# ioat91sam7s64 register map
Registers are 32-bit, access not given, no defined reset value unless marked. A register's access mark holds for its fields unless they carry their own. Addresses are absolute; registers are grouped by the start of their names; [hi:lo] are bit positions; {n}, {i} and the like mark numbered series; 'fields as' and 'values as' point back to an identical list.

## RSTC
0xFFFFFD00 RSTC_RCR 40-bit
  [32:24] KEY, [3] EXTRST, [2] PERRST, [1] ICERST, [0] PROCRST
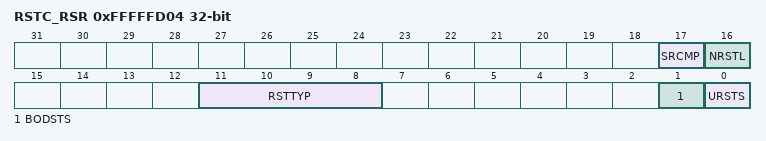
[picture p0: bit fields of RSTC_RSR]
0xFFFFFD04 RSTC_RSR
  [17] SRCMP, [16] NRSTL, [11:8] RSTTYP, [1] BODSTS, [0] URSTS
0xFFFFFD08 RSTC_RMR 40-bit
  [32:24] KEY, [16] BODIEN, [12:8] ERSTL, [4] URSTIEN, [0] URSTEN

## RTTC
0xFFFFFD20 RTTC_RTMR
  [18] RTTRST, [17] RTTINCIEN, [16] ALMIEN, [16:0] RTPRES
0xFFFFFD24 RTTC_RTAR 40-bit
  [32:0] ALMV
0xFFFFFD28 RTTC_RTVR 40-bit
  [32:0] CRTV
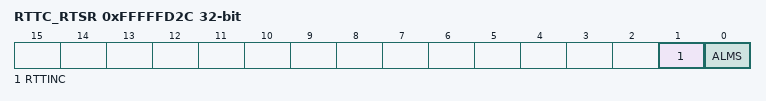
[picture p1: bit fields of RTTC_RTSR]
0xFFFFFD2C RTTC_RTSR
  [1] RTTINC, [0] ALMS

## PITC
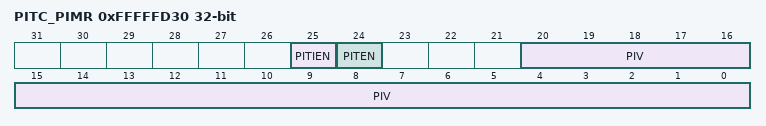
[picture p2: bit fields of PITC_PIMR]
0xFFFFFD30 PITC_PIMR
  [25] PITIEN, [24] PITEN, [20:0] PIV
0xFFFFFD34 PITC_PISR
  [0] PITS
0xFFFFFD38 PITC_PIVR 40-bit
  [32:20] PICNT, [20:0] CPIV
0xFFFFFD3C PITC_PIIR 40-bit
  [32:20] PICNT, [20:0] CPIV

## WDTC
0xFFFFFD40 WDTC_WDCR 40-bit
  [32:24] KEY, [0] WDRSTT
0xFFFFFD44 WDTC_WDMR
  [29] WDIDLEHLT, [28] WDDBGHLT, [28:16] WDD, [15] WDDIS, [14] WDRPROC, [13] WDRSTEN, [12] WDFIEN, [12:0] WDV
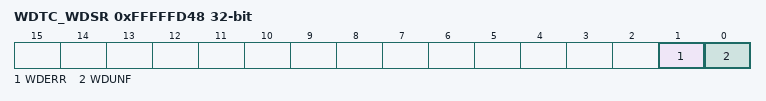
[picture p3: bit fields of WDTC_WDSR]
0xFFFFFD48 WDTC_WDSR
  [1] WDERR, [0] WDUNF

## MC
0xFFFFFF00 MC_RCR
  [0] RCB
0xFFFFFF04 MC_ASR
  [25] SVMST1, [24] SVMST0, [17] MST1, [16] MST0, [12:10] ABTTYP, [10:8] ABTSZ, [1] MISADD, [0] UNDADD
0xFFFFFF08 MC_AASR
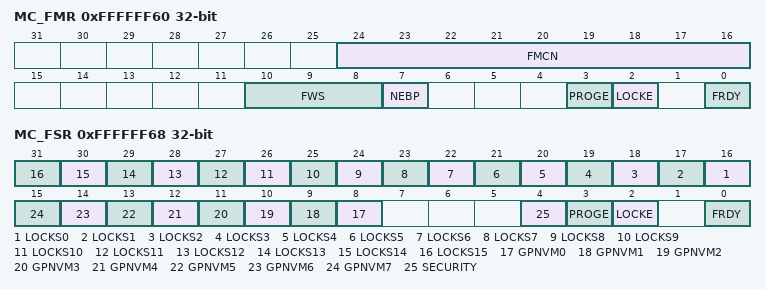
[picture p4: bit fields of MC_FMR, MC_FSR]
0xFFFFFF60 MC_FMR
  [24:16] FMCN, [10:8] FWS, [7] NEBP, [3] PROGE, [2] LOCKE, [0] FRDY
0xFFFFFF64 MC_FCR 40-bit
  [32:24] KEY, [18:8] PAGEN, [4:0] FCMD
0xFFFFFF68 MC_FSR
  [n+16] LOCKS{n} (n=0..15), [n+8] GPNVM{n} (n=0..7), [4] SECURITY, [3] PROGE, [2] LOCKE, [0] FRDY

## SPI
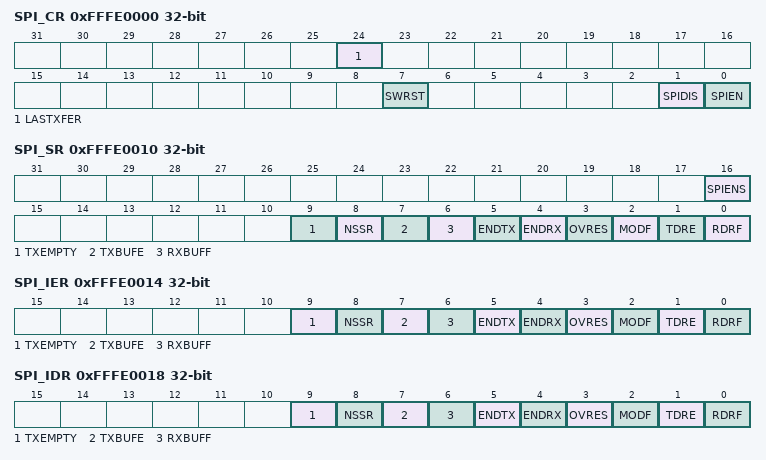
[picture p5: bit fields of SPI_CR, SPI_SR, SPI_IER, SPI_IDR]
0xFFFE0000 SPI_CR
  [24] LASTXFER, [7] SWRST, [1] SPIDIS, [0] SPIEN
0xFFFE0004 SPI_MR 40-bit
  [32:24] DLYBCS, [20:16] PCS, [7] LLB, [4] MODFDIS, [3] FDIV, [2] PCSDEC, [1] PS, [0] MSTR
0xFFFE0008 SPI_RDR
  [20:16] RPCS, [16:0] RD
0xFFFE000C SPI_TDR
  [24] LASTXFER, [20:16] TPCS, [16:0] TD
0xFFFE0010 SPI_SR
  [16] SPIENS, [9] TXEMPTY, [8] NSSR, [7] TXBUFE, [6] RXBUFF, [5] ENDTX, [4] ENDRX, [3] OVRES, [2] MODF, [1] TDRE, [0] RDRF
0xFFFE0014 SPI_IER
  [9] TXEMPTY, [8] NSSR, [7] TXBUFE, [6] RXBUFF, [5] ENDTX, [4] ENDRX, [3] OVRES, [2] MODF, [1] TDRE, [0] RDRF
0xFFFE0018 SPI_IDR
  fields as SPI_IER
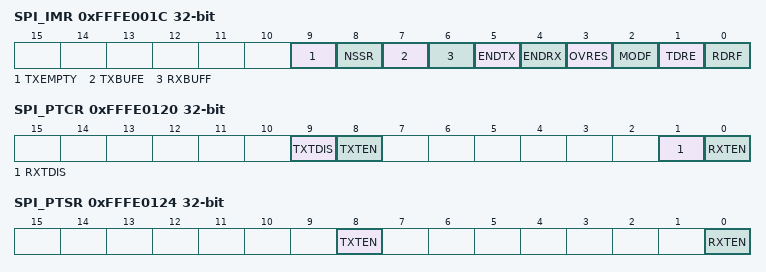
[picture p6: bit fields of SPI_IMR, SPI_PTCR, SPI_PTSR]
0xFFFE001C SPI_IMR
  fields as SPI_IER
0xFFFE0030 SPI_CSR 40-bit
  [32:24] DLYBCT, [24:16] DLYBS, [16:8] SCBR, [8:4] BITS, [2] CSAAT, [1] NCPHA, [0] CPOL
0xFFFE0100 SPI_RPR
0xFFFE0104 SPI_RCR
0xFFFE0108 SPI_TPR
0xFFFE010C SPI_TCR
0xFFFE0110 SPI_RNPR
0xFFFE0114 SPI_RNCR
0xFFFE0118 SPI_TNPR
0xFFFE011C SPI_TNCR
0xFFFE0120 SPI_PTCR
  [9] TXTDIS, [8] TXTEN, [1] RXTDIS, [0] RXTEN
0xFFFE0124 SPI_PTSR
  [8] TXTEN, [0] RXTEN

## ADC
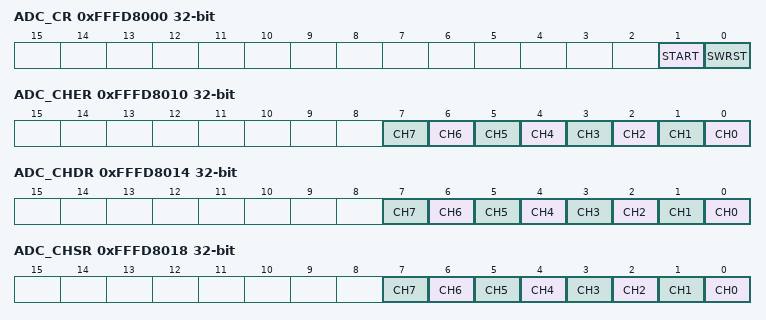
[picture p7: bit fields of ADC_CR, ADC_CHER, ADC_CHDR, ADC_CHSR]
0xFFFD8000 ADC_CR
  [1] START, [0] SWRST
0xFFFD8004 ADC_MR
  [28:24] SHTIM, [21:16] STARTUP, [14:8] PRESCAL, [5] SLEEP, [4] LOWRES, [4:1] TRGSEL, [0] TRGEN
0xFFFD8010 ADC_CHER
  [n] CH{n} (n=0..7)
0xFFFD8014 ADC_CHDR
  [n] CH{n} (n=0..7)
0xFFFD8018 ADC_CHSR
  [n] CH{n} (n=0..7)
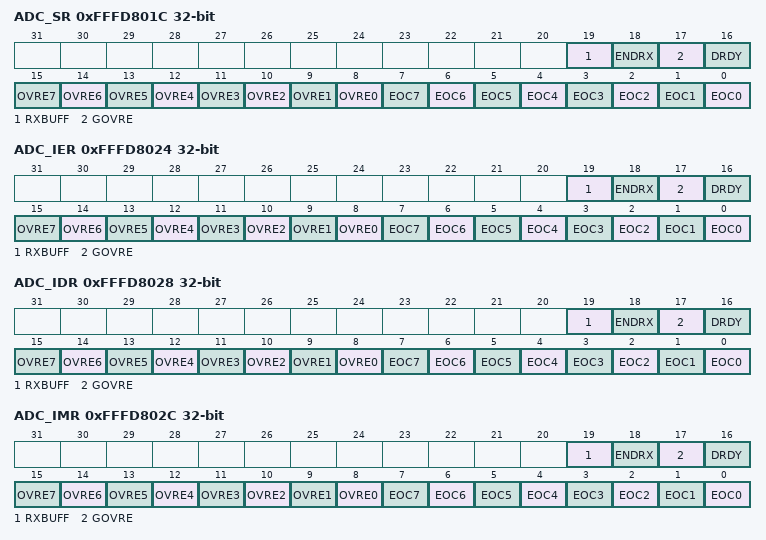
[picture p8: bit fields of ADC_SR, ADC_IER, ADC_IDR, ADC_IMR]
0xFFFD801C ADC_SR
  [19] RXBUFF, [18] ENDRX, [17] GOVRE, [16] DRDY, [n+8] OVRE{n} (n=0..7), [n] EOC{n} (n=0..7)
0xFFFD8020 ADC_LCDR
  [10:0] LDATA
0xFFFD8024 ADC_IER
  fields as ADC_SR
0xFFFD8028 ADC_IDR
  fields as ADC_SR
0xFFFD802C ADC_IMR
  fields as ADC_SR
{0xFFFD8030+4i} ADC_CDR{i} (i=0..7)
  [10:0] DATA
0xFFFD8100 ADC_RPR
0xFFFD8104 ADC_RCR
0xFFFD8108 ADC_TPR
0xFFFD810C ADC_TCR
0xFFFD8110 ADC_RNPR
0xFFFD8114 ADC_RNCR
0xFFFD8118 ADC_TNPR
0xFFFD811C ADC_TNCR
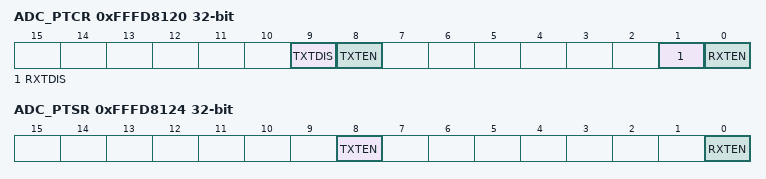
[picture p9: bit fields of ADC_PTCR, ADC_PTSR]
0xFFFD8120 ADC_PTCR
  [9] TXTDIS, [8] TXTEN, [1] RXTDIS, [0] RXTEN
0xFFFD8124 ADC_PTSR
  [8] TXTEN, [0] RXTEN

## SSC
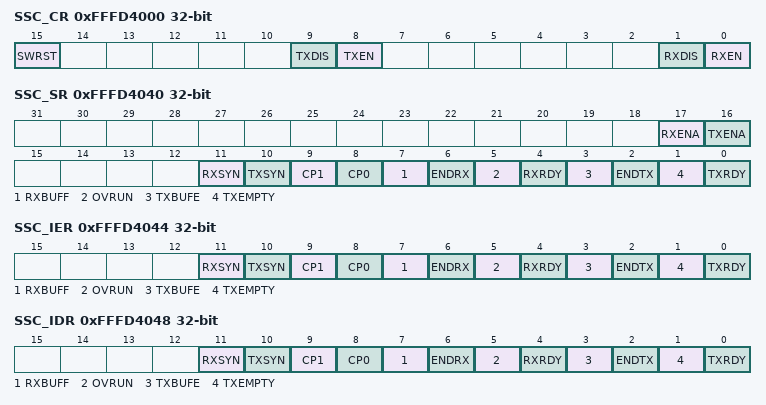
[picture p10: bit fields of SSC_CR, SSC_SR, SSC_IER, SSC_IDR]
0xFFFD4000 SSC_CR
  [15] SWRST, [9] TXDIS, [8] TXEN, [1] RXDIS, [0] RXEN
0xFFFD4004 SSC_CMR
0xFFFD4010 SSC_RCMR 40-bit
  [32:24] PERIOD, [24:16] STTDLY, [15] STTOUT, [12] STOP, [12:8] START, [8:6] CKG, [5] CKI, [5:2] CKO, [2:0] CKS
0xFFFD4014 SSC_RFMR
  [24] FSEDGE, [23:20] FSOS, [20:16] FSLEN, [12:8] DATNB, [7] MSBF, [5] LOOP, [5:0] DATLEN
0xFFFD4018 SSC_TCMR 40-bit
  [32:24] PERIOD, [24:16] STTDLY, [15] STTOUT, [12:8] START, [8:6] CKG, [5] CKI, [5:2] CKO, [2:0] CKS
0xFFFD401C SSC_TFMR
  [24] FSEDGE, [23] FSDEN, [23:20] FSOS, [20:16] FSLEN, [12:8] DATNB, [7] MSBF, [5] DATDEF, [5:0] DATLEN
0xFFFD4020 SSC_RHR
0xFFFD4024 SSC_THR
0xFFFD4030 SSC_RSHR
0xFFFD4034 SSC_TSHR
0xFFFD4038 SSC_RC0R
0xFFFD403C SSC_RC1R
0xFFFD4040 SSC_SR
  [17] RXENA, [16] TXENA, [11] RXSYN, [10] TXSYN, [9] CP1, [8] CP0, [7] RXBUFF, [6] ENDRX, [5] OVRUN, [4] RXRDY, [3] TXBUFE, [2] ENDTX, [1] TXEMPTY, [0] TXRDY
0xFFFD4044 SSC_IER
  [11] RXSYN, [10] TXSYN, [9] CP1, [8] CP0, [7] RXBUFF, [6] ENDRX, [5] OVRUN, [4] RXRDY, [3] TXBUFE, [2] ENDTX, [1] TXEMPTY, [0] TXRDY
0xFFFD4048 SSC_IDR
  fields as SSC_IER
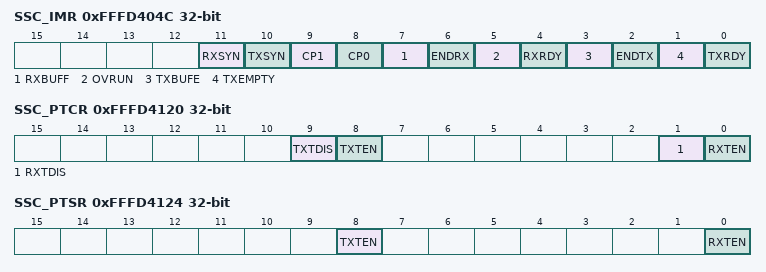
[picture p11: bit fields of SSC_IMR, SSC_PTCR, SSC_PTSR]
0xFFFD404C SSC_IMR
  fields as SSC_IER
0xFFFD4100 SSC_RPR
0xFFFD4104 SSC_RCR
0xFFFD4108 SSC_TPR
0xFFFD410C SSC_TCR
0xFFFD4110 SSC_RNPR
0xFFFD4114 SSC_RNCR
0xFFFD4118 SSC_TNPR
0xFFFD411C SSC_TNCR
0xFFFD4120 SSC_PTCR
  [9] TXTDIS, [8] TXTEN, [1] RXTDIS, [0] RXTEN
0xFFFD4124 SSC_PTSR
  [8] TXTEN, [0] RXTEN
